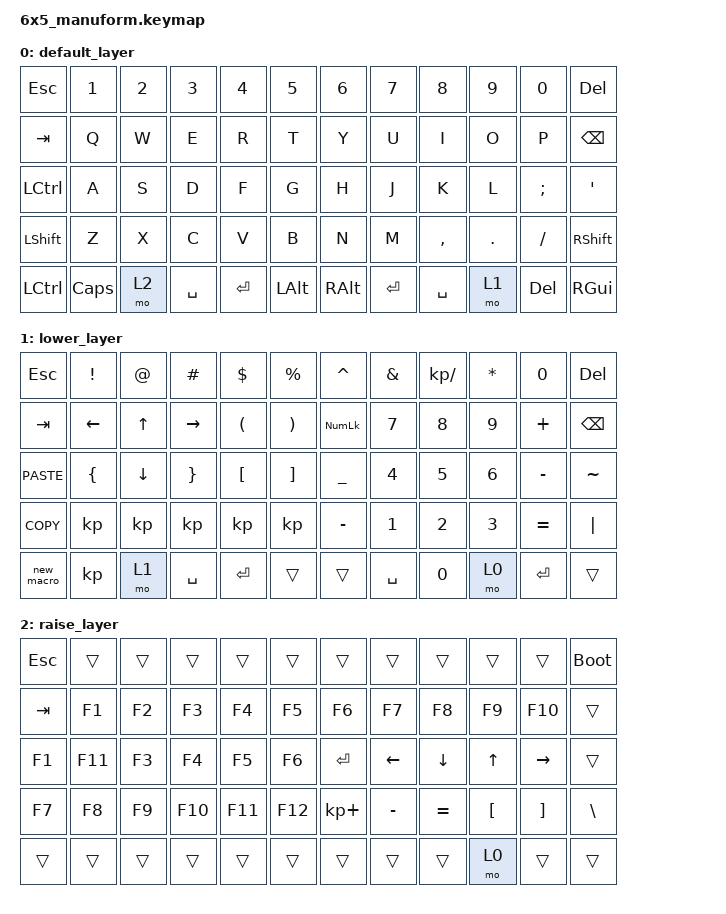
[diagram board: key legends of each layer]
/*
 * Copyright (c) 2020 The ZMK Contributors
 *
 * SPDX-License-Identifier: MIT
 */

#include <behaviors.dtsi>
#include <dt-bindings/zmk/keys.h>

/ {
    macros {
        new_macro: new_macro {
            compatible = "zmk,behavior-macro";
            label = "new_macro 1";
            #binding-cells = <0>;
            bindings = <&kp LS(I) &kp N &kp E &kp E &kp D &kp M &kp O &kp R &kp E &kp T &kp H &kp A &kp N &kp N2 &kp N4 &kp H &kp EXCL>;
        };
    };

    keymap {
        compatible = "zmk,keymap";

        default_layer {
            // ------------------------------------------------------------------------------------------------------------
            // |  ESC   |  1  |  2  |  3   |  4   |  5   |                    |  6   |  7    |  8    |  9   |   0   |   `   |
            // |  TAB   |  Q  |  W  |  E   |  R   |  T   |                    |  Y   |  U    |  I    |  O   |   P   |   -   |
            // |  CTRL  |  A  |  S  |  D   |  F   |  G   |                    |  H   |  J    |  K    |  L   |   ;   |   '   |
            // | SHIFT  |  Z  |  X  |  C   |  V   |  B   |                    |  N   |  M    |  ,    |  .   |   /   | SHIFT |
            // |    2   |  2  | f   | 6    | 4    | 1    |                    | 2    | 1     | w     | s    | n     |  a    |

            bindings = <
          &kp ESC    &kp N1  &kp N2     &kp N3     &kp N4    &kp N5    &kp N6   &kp N7     &kp N8   &kp N9    &kp N0          &kp DEL
          &kp TAB     &kp Q   &kp W      &kp E      &kp R     &kp T     &kp Y    &kp U      &kp I    &kp O     &kp P    &kp BACKSPACE
 &kp LEFT_CONTROL     &kp A   &kp S      &kp D      &kp F     &kp G     &kp H    &kp J      &kp K    &kp L  &kp SEMI          &kp SQT
   &kp LEFT_SHIFT     &kp Z   &kp X      &kp C      &kp V     &kp B     &kp N    &kp M  &kp COMMA  &kp DOT  &kp FSLH  &kp RIGHT_SHIFT
        &kp LCTRL  &kp CAPS   &mo 2  &kp SPACE  &kp ENTER  &kp LALT  &kp RALT  &kp RET  &kp SPACE    &mo 1   &kp DEL    &kp RIGHT_GUI
            >;

            sensor-bindings = <&inc_dec_kp C_VOL_UP C_VOL_DN>;
        };

        lower_layer {
            // ------------------------------------------------------------------------------------------------------------
            // | BTCLR | BT1 | BT2 |  BT3 |  BT4 |  BT5 |                   |      |       |       |      |       |       |
            // |  F1   |  F2 |  F3 |  F4  |  F5  |  F6  |                   |  F7  |  F8   |  F9   |  F10 |  F11  |  F12  |
            // |   `   |  !  |  @  |  #   |  $   |  %   |                   |  ^   |  &    |  *    |  (   |   )   |   ~   |
            // |       |     |     |      |      |      |                   |      |  _    |  +    |  {   |   }   |  "|"  |
            // |       |     |     |      |      |      |                   |      |       |       |      |       |       |

            bindings = <
     &kp ESC  &kp EXCLAMATION        &kp AT        &kp POUND            &kp DOLLAR            &kp PERCENT       &kp CARET  &kp AMPERSAND  &kp KP_DIVIDE  &kp ASTERISK  &kp NUMBER_0        &kp DEL
     &kp TAB   &kp LEFT_ARROW  &kp UP_ARROW  &kp RIGHT_ARROW  &kp LEFT_PARENTHESIS  &kp RIGHT_PARENTHESIS  &kp KP_NUMLOCK   &kp NUMBER_7   &kp NUMBER_8  &kp NUMBER_9      &kp PLUS  &kp BACKSPACE
 &kp K_PASTE   &kp LEFT_BRACE      &kp DOWN  &kp RIGHT_BRACE      &kp LEFT_BRACKET      &kp RIGHT_BRACKET       &kp UNDER   &kp NUMBER_4   &kp NUMBER_5  &kp NUMBER_6     &kp MINUS      &kp TILDE
  &kp K_COPY              &kp           &kp              &kp                   &kp                    &kp       &kp MINUS   &kp NUMBER_1   &kp NUMBER_2  &kp NUMBER_3     &kp EQUAL       &kp PIPE
  &new_macro              &kp         &mo 1        &kp SPACE             &kp ENTER                 &trans          &trans      &kp SPACE   &kp NUMBER_0         &mo 0     &kp ENTER         &trans
            >;

            sensor-bindings = <&inc_dec_kp C_VOL_UP C_VOL_DN>;
        };

        raise_layer {
            // ------------------------------------------------------------------------------------------------------------
            // |       |     |     |      |      |      |                   |      |       |       |      |       |       |
            // |   `   |  1  |  2  |  3   |  4   |  5   |                   |  6   |   7   |   8   |  9   |   0   |       |
            // |   F1  |  F2 |  F3 |  F4  |  F5  |  F6  |                   |      |   <-  |   v   |  ^   |  ->   |       |
            // |   F7  |  F8 |  F9 |  F10 |  F11 |  F12 |		             |  +   |   -   |   =   |  [   |   ]   |   \   |
            // |     |     |      |      |      |        |                   |       |      |       |       |      |       |

            bindings = <
 &kp ESC   &trans  &trans   &trans   &trans   &trans       &trans     &trans     &trans    &trans     &trans  &bootloader
 &kp TAB   &kp F1  &kp F2   &kp F3   &kp F4   &kp F5       &kp F6     &kp F7     &kp F8    &kp F9    &kp F10       &trans
  &kp F1  &kp F11  &kp F3   &kp F4   &kp F5   &kp F6      &kp RET   &kp LEFT   &kp DOWN    &kp UP  &kp RIGHT       &trans
  &kp F7   &kp F8  &kp F9  &kp F10  &kp F11  &kp F12  &kp KP_PLUS  &kp MINUS  &kp EQUAL  &kp LBKT   &kp RBKT     &kp BSLH
  &trans   &trans  &trans   &trans   &trans   &trans       &trans     &trans     &trans     &mo 0     &trans       &trans
            >;

            sensor-bindings = <&inc_dec_kp C_VOL_UP C_VOL_DN>;
        };
    };
};
